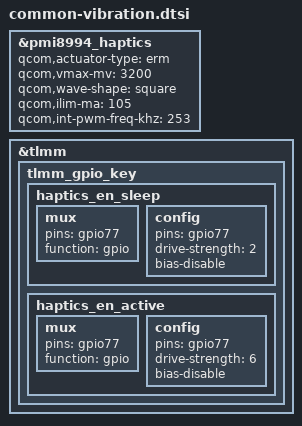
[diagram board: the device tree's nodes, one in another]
&pmi8994_haptics {
	qcom,actuator-type = "erm";
	qcom,vmax-mv = <3200>;
	qcom,wave-shape = "square";
	//qcom,wave-play-rate-us = <5263>;//0~20475
	qcom,ilim-ma = <105>;
	qcom,int-pwm-freq-khz = <253>;//lowest:253Khz
};

&tlmm {
	tlmm_gpio_key {
        haptics_en_sleep: haptics_en_sleep {
			mux {
				pins = "gpio77";
				function = "gpio";
			};

			config {
				pins = "gpio77";
				drive-strength = <2>;   /* 2 mA */
				bias-disable;           /* NO PULL */
			};
		};
		haptics_en_active: haptics_en_active {
			mux {
				pins = "gpio77";
				function = "gpio";
			};

			config {
				pins = "gpio77";
				drive-strength = <6>;   /* 8 mA */
				bias-disable;           /* NO PULL */
			};
		};
    };
};
